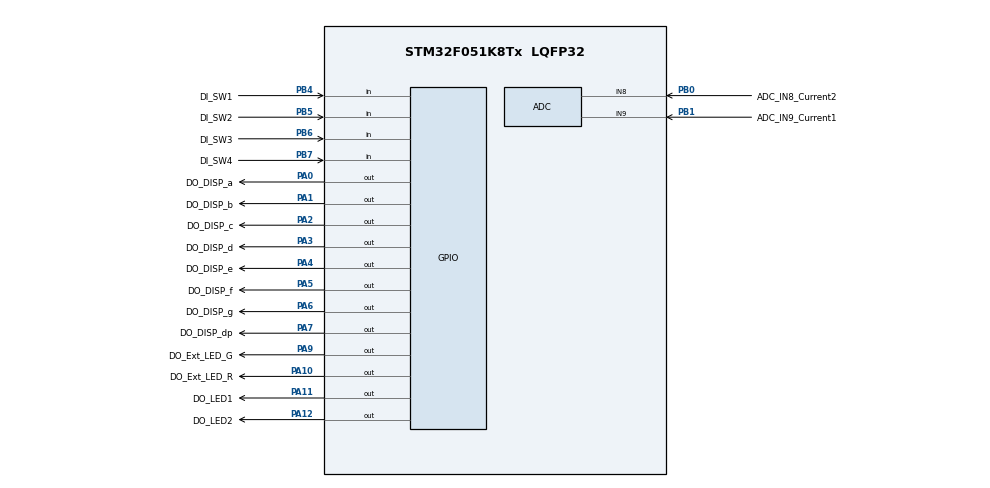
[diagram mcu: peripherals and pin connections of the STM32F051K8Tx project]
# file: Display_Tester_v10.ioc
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ADC.ClockPrescaler=ADC_CLOCK_ASYNC_DIV1
ADC.ContinuousConvMode=ENABLE
ADC.DMAContinuousRequests=ENABLE
ADC.EOCSelection=ADC_EOC_SINGLE_CONV
ADC.SamplingTime=ADC_SAMPLETIME_239CYCLES_5
Dma.ADC.0.Direction=DMA_PERIPH_TO_MEMORY
Dma.ADC.0.Instance=DMA1_Channel1
Dma.ADC.0.MemDataAlignment=DMA_MDATAALIGN_HALFWORD
Dma.ADC.0.MemInc=DMA_MINC_ENABLE
Dma.ADC.0.Mode=DMA_CIRCULAR
Dma.ADC.0.PeriphDataAlignment=DMA_PDATAALIGN_HALFWORD
Dma.ADC.0.PeriphInc=DMA_PINC_DISABLE
Dma.ADC.0.Priority=DMA_PRIORITY_LOW
Dma.Request0=ADC
Mcu.Family=STM32F0
Mcu.Name=STM32F051K8Tx
Mcu.Package=LQFP32
NVIC.DMA1_Channel1_IRQn=true\:0\:0\:false\:false\:true\:false\:true
PA0.GPIO_Label=DO_DISP_a
PA0.Signal=GPIO_Output
PA1.GPIO_Label=DO_DISP_b
PA1.Signal=GPIO_Output
PA10.GPIO_Label=DO_Ext_LED_R
PA10.Signal=GPIO_Output
PA11.GPIO_Label=DO_LED1
PA11.Signal=GPIO_Output
PA12.GPIO_Label=DO_LED2
PA12.Signal=GPIO_Output
PA13.Mode=Serial_Wire
PA13.Signal=SYS_SWDIO
PA14.Mode=Serial_Wire
PA14.Signal=SYS_SWCLK
PA2.GPIO_Label=DO_DISP_c
PA2.Signal=GPIO_Output
PA3.GPIO_Label=DO_DISP_d
PA3.Signal=GPIO_Output
PA4.GPIO_Label=DO_DISP_e
PA4.Signal=GPIO_Output
PA5.GPIO_Label=DO_DISP_f
PA5.Signal=GPIO_Output
PA6.GPIO_Label=DO_DISP_g
PA6.Signal=GPIO_Output
PA7.GPIO_Label=DO_DISP_dp
PA7.Signal=GPIO_Output
PA9.GPIO_Label=DO_Ext_LED_G
PA9.Signal=GPIO_Output
PB0.GPIO_Label=ADC_IN8_Current2
PB0.Mode=IN8
PB0.Signal=ADC_IN8
PB1.GPIO_Label=ADC_IN9_Current1
PB1.Mode=IN9
PB1.Signal=ADC_IN9
PB4.GPIO_Label=DI_SW1
PB4.GPIO_PuPd=GPIO_PULLUP
PB4.Signal=GPIO_Input
PB5.GPIO_Label=DI_SW2
PB5.GPIO_PuPd=GPIO_PULLUP
PB5.Signal=GPIO_Input
PB6.GPIO_Label=DI_SW3
PB6.GPIO_PuPd=GPIO_PULLUP
PB6.Signal=GPIO_Input
PB7.GPIO_Label=DI_SW4
PB7.GPIO_PuPd=GPIO_PULLUP
PB7.Signal=GPIO_Input
PF0-OSC_IN.Mode=HSE-External-Oscillator
PF0-OSC_IN.Signal=RCC_OSC_IN
PF1-OSC_OUT.Mode=HSE-External-Oscillator
PF1-OSC_OUT.Signal=RCC_OSC_OUT
ProjectManager.HeapSize=0x200
ProjectManager.StackSize=0x400
ProjectManager.TargetToolchain=STM32CubeIDE
RCC.AHBFreq_Value=48000000
RCC.APB1Freq_Value=48000000
RCC.APB1TimFreq_Value=48000000
RCC.HCLKFreq_Value=48000000
RCC.PLLMUL=RCC_PLL_MUL6
RCC.PLLSourceVirtual=RCC_PLLSOURCE_HSE
RCC.SYSCLKFreq_VALUE=48000000
RCC.SYSCLKSource=RCC_SYSCLKSOURCE_PLLCLK
board=custom

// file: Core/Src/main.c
/* USER CODE BEGIN Header */
/**
  ******************************************************************************
  * @file           : main.c
  * @brief          : Main program body
  ******************************************************************************
  * @attention
  *
  * <h2><center>&copy; Copyright (c) 2020 STMicroelectronics.
  * All rights reserved.</center></h2>
  *
  * This software component is licensed by ST under BSD 3-Clause license,
  * the "License"; You may not use this file except in compliance with the
  * License. You may obtain a copy of the License at:
  *                        opensource.org/licenses/BSD-3-Clause
  *
  ******************************************************************************
  */
/* USER CODE END Header */
#include "main.h"

ADC_HandleTypeDef hadc;
DMA_HandleTypeDef hdma_adc;

void SystemClock_Config(void);
static void MX_GPIO_Init(void);
static void MX_DMA_Init(void);
static void MX_ADC_Init(void);

int main(void)
{

  /* MCU Configuration--------------------------------------------------------*/

  /* Reset of all peripherals, Initializes the Flash interface and the Systick. */
  HAL_Init();

  /* Configure the system clock */
  SystemClock_Config();

  /* Initialize all configured peripherals */
  MX_GPIO_Init();
  MX_DMA_Init();
  MX_ADC_Init();
  /* USER CODE BEGIN 2 */

  Tester_Init();

  /* USER CODE END 2 */

  /* Infinite loop */
  /* USER CODE BEGIN WHILE */
  while (1)
  {
	  Tester_ProcessingTask();

    /* USER CODE END WHILE */

  }
}

void SystemClock_Config(void)
{
  LL_FLASH_SetLatency(LL_FLASH_LATENCY_1);
  while(LL_FLASH_GetLatency() != LL_FLASH_LATENCY_1)
  {
  }
  LL_RCC_HSE_Enable();

   /* Wait till HSE is ready */
  while(LL_RCC_HSE_IsReady() != 1)
  {

  }
  LL_RCC_HSI14_Enable();

   /* Wait till HSI14 is ready */
  while(LL_RCC_HSI14_IsReady() != 1)
  {

  }
  LL_RCC_HSI14_SetCalibTrimming(16);
  LL_RCC_PLL_ConfigDomain_SYS(LL_RCC_PLLSOURCE_HSE_DIV_1, LL_RCC_PLL_MUL_6);
  LL_RCC_PLL_Enable();

   /* Wait till PLL is ready */
  while(LL_RCC_PLL_IsReady() != 1)
  {

  }
  LL_RCC_SetAHBPrescaler(LL_RCC_SYSCLK_DIV_1);
  LL_RCC_SetAPB1Prescaler(LL_RCC_APB1_DIV_1);
  LL_RCC_SetSysClkSource(LL_RCC_SYS_CLKSOURCE_PLL);

   /* Wait till System clock is ready */
  while(LL_RCC_GetSysClkSource() != LL_RCC_SYS_CLKSOURCE_STATUS_PLL)
  {

  }
  LL_SetSystemCoreClock(48000000);

   /* Update the time base */
  if (HAL_InitTick (TICK_INT_PRIORITY) != HAL_OK)
  {
    Error_Handler();
  }
  LL_RCC_HSI14_EnableADCControl();
}

static void MX_ADC_Init(void)
{

  ADC_ChannelConfTypeDef sConfig = {0};

  /** Configure the global features of the ADC (Clock, Resolution, Data Alignment and number of conversion)
  */
  hadc.Instance = ADC1;
  hadc.Init.ClockPrescaler = ADC_CLOCK_ASYNC_DIV1;
  hadc.Init.Resolution = ADC_RESOLUTION_12B;
  hadc.Init.DataAlign = ADC_DATAALIGN_RIGHT;
  hadc.Init.ScanConvMode = ADC_SCAN_DIRECTION_FORWARD;
  hadc.Init.EOCSelection = ADC_EOC_SINGLE_CONV;
  hadc.Init.LowPowerAutoWait = DISABLE;
  hadc.Init.LowPowerAutoPowerOff = DISABLE;
  hadc.Init.ContinuousConvMode = ENABLE;
  hadc.Init.DiscontinuousConvMode = DISABLE;
  hadc.Init.ExternalTrigConv = ADC_SOFTWARE_START;
  hadc.Init.ExternalTrigConvEdge = ADC_EXTERNALTRIGCONVEDGE_NONE;
  hadc.Init.DMAContinuousRequests = ENABLE;
  hadc.Init.Overrun = ADC_OVR_DATA_PRESERVED;
  if (HAL_ADC_Init(&hadc) != HAL_OK)
  {
    Error_Handler();
  }
  /** Configure for the selected ADC regular channel to be converted.
  */
  sConfig.Channel = ADC_CHANNEL_8;
  sConfig.Rank = ADC_RANK_CHANNEL_NUMBER;
  sConfig.SamplingTime = ADC_SAMPLETIME_239CYCLES_5;
  if (HAL_ADC_ConfigChannel(&hadc, &sConfig) != HAL_OK)
  {
    Error_Handler();
  }
  /** Configure for the selected ADC regular channel to be converted.
  */
  sConfig.Channel = ADC_CHANNEL_9;
  if (HAL_ADC_ConfigChannel(&hadc, &sConfig) != HAL_OK)
  {
    Error_Handler();
  }

}

static void MX_DMA_Init(void)
{

  /* DMA controller clock enable */
  __HAL_RCC_DMA1_CLK_ENABLE();

  /* DMA interrupt init */
  /* DMA1_Channel1_IRQn interrupt configuration */
  HAL_NVIC_SetPriority(DMA1_Channel1_IRQn, 0, 0);
  HAL_NVIC_EnableIRQ(DMA1_Channel1_IRQn);

}

static void MX_GPIO_Init(void)
{
  LL_GPIO_InitTypeDef GPIO_InitStruct = {0};

  /* GPIO Ports Clock Enable */
  LL_AHB1_GRP1_EnableClock(LL_AHB1_GRP1_PERIPH_GPIOF);
  LL_AHB1_GRP1_EnableClock(LL_AHB1_GRP1_PERIPH_GPIOA);
  LL_AHB1_GRP1_EnableClock(LL_AHB1_GRP1_PERIPH_GPIOB);

  /**/
  LL_GPIO_ResetOutputPin(DO_DISP_a_GPIO_Port, DO_DISP_a_Pin);

  /**/
  LL_GPIO_ResetOutputPin(DO_DISP_b_GPIO_Port, DO_DISP_b_Pin);

  /**/
  LL_GPIO_ResetOutputPin(DO_DISP_c_GPIO_Port, DO_DISP_c_Pin);

  /**/
  LL_GPIO_ResetOutputPin(DO_DISP_d_GPIO_Port, DO_DISP_d_Pin);

  /**/
  LL_GPIO_ResetOutputPin(DO_DISP_e_GPIO_Port, DO_DISP_e_Pin);

  /**/
  LL_GPIO_ResetOutputPin(DO_DISP_f_GPIO_Port, DO_DISP_f_Pin);

  /**/
  LL_GPIO_ResetOutputPin(DO_DISP_g_GPIO_Port, DO_DISP_g_Pin);

  /**/
  LL_GPIO_ResetOutputPin(DO_DISP_dp_GPIO_Port, DO_DISP_dp_Pin);

  /**/
  LL_GPIO_ResetOutputPin(DO_Ext_LED_G_GPIO_Port, DO_Ext_LED_G_Pin);

  /**/
  LL_GPIO_ResetOutputPin(DO_Ext_LED_R_GPIO_Port, DO_Ext_LED_R_Pin);

  /**/
  LL_GPIO_ResetOutputPin(DO_LED1_GPIO_Port, DO_LED1_Pin);

  /**/
  LL_GPIO_ResetOutputPin(DO_LED2_GPIO_Port, DO_LED2_Pin);

  /**/
  GPIO_InitStruct.Pin = DO_DISP_a_Pin;
  GPIO_InitStruct.Mode = LL_GPIO_MODE_OUTPUT;
  GPIO_InitStruct.Speed = LL_GPIO_SPEED_FREQ_LOW;
  GPIO_InitStruct.OutputType = LL_GPIO_OUTPUT_PUSHPULL;
  GPIO_InitStruct.Pull = LL_GPIO_PULL_NO;
  LL_GPIO_Init(DO_DISP_a_GPIO_Port, &GPIO_InitStruct);

  /**/
  GPIO_InitStruct.Pin = DO_DISP_b_Pin;
  GPIO_InitStruct.Mode = LL_GPIO_MODE_OUTPUT;
  GPIO_InitStruct.Speed = LL_GPIO_SPEED_FREQ_LOW;
  GPIO_InitStruct.OutputType = LL_GPIO_OUTPUT_PUSHPULL;
  GPIO_InitStruct.Pull = LL_GPIO_PULL_NO;
  LL_GPIO_Init(DO_DISP_b_GPIO_Port, &GPIO_InitStruct);

  /**/
  GPIO_InitStruct.Pin = DO_DISP_c_Pin;
  GPIO_InitStruct.Mode = LL_GPIO_MODE_OUTPUT;
  GPIO_InitStruct.Speed = LL_GPIO_SPEED_FREQ_LOW;
  GPIO_InitStruct.OutputType = LL_GPIO_OUTPUT_PUSHPULL;
  GPIO_InitStruct.Pull = LL_GPIO_PULL_NO;
  LL_GPIO_Init(DO_DISP_c_GPIO_Port, &GPIO_InitStruct);

  /**/
  GPIO_InitStruct.Pin = DO_DISP_d_Pin;
  GPIO_InitStruct.Mode = LL_GPIO_MODE_OUTPUT;
  GPIO_InitStruct.Speed = LL_GPIO_SPEED_FREQ_LOW;
  GPIO_InitStruct.OutputType = LL_GPIO_OUTPUT_PUSHPULL;
  GPIO_InitStruct.Pull = LL_GPIO_PULL_NO;
  LL_GPIO_Init(DO_DISP_d_GPIO_Port, &GPIO_InitStruct);

  /**/
  GPIO_InitStruct.Pin = DO_DISP_e_Pin;
  GPIO_InitStruct.Mode = LL_GPIO_MODE_OUTPUT;
  GPIO_InitStruct.Speed = LL_GPIO_SPEED_FREQ_LOW;
  GPIO_InitStruct.OutputType = LL_GPIO_OUTPUT_PUSHPULL;
  GPIO_InitStruct.Pull = LL_GPIO_PULL_NO;
  LL_GPIO_Init(DO_DISP_e_GPIO_Port, &GPIO_InitStruct);

  /**/
  GPIO_InitStruct.Pin = DO_DISP_f_Pin;
  GPIO_InitStruct.Mode = LL_GPIO_MODE_OUTPUT;
  GPIO_InitStruct.Speed = LL_GPIO_SPEED_FREQ_LOW;
  GPIO_InitStruct.OutputType = LL_GPIO_OUTPUT_PUSHPULL;
  GPIO_InitStruct.Pull = LL_GPIO_PULL_NO;
  LL_GPIO_Init(DO_DISP_f_GPIO_Port, &GPIO_InitStruct);

  /**/
  GPIO_InitStruct.Pin = DO_DISP_g_Pin;
  GPIO_InitStruct.Mode = LL_GPIO_MODE_OUTPUT;
  GPIO_InitStruct.Speed = LL_GPIO_SPEED_FREQ_LOW;
  GPIO_InitStruct.OutputType = LL_GPIO_OUTPUT_PUSHPULL;
  GPIO_InitStruct.Pull = LL_GPIO_PULL_NO;
  LL_GPIO_Init(DO_DISP_g_GPIO_Port, &GPIO_InitStruct);

  /**/
  GPIO_InitStruct.Pin = DO_DISP_dp_Pin;
  GPIO_InitStruct.Mode = LL_GPIO_MODE_OUTPUT;
  GPIO_InitStruct.Speed = LL_GPIO_SPEED_FREQ_LOW;
  GPIO_InitStruct.OutputType = LL_GPIO_OUTPUT_PUSHPULL;
  GPIO_InitStruct.Pull = LL_GPIO_PULL_NO;
  LL_GPIO_Init(DO_DISP_dp_GPIO_Port, &GPIO_InitStruct);

  /**/
  GPIO_InitStruct.Pin = LL_GPIO_PIN_8;
  GPIO_InitStruct.Mode = LL_GPIO_MODE_ANALOG;
  GPIO_InitStruct.Pull = LL_GPIO_PULL_NO;
  LL_GPIO_Init(GPIOA, &GPIO_InitStruct);

  /**/
  GPIO_InitStruct.Pin = DO_Ext_LED_G_Pin;
  GPIO_InitStruct.Mode = LL_GPIO_MODE_OUTPUT;
  GPIO_InitStruct.Speed = LL_GPIO_SPEED_FREQ_LOW;
  GPIO_InitStruct.OutputType = LL_GPIO_OUTPUT_PUSHPULL;
  GPIO_InitStruct.Pull = LL_GPIO_PULL_NO;
  LL_GPIO_Init(DO_Ext_LED_G_GPIO_Port, &GPIO_InitStruct);

  /**/
  GPIO_InitStruct.Pin = DO_Ext_LED_R_Pin;
  GPIO_InitStruct.Mode = LL_GPIO_MODE_OUTPUT;
  GPIO_InitStruct.Speed = LL_GPIO_SPEED_FREQ_LOW;
  GPIO_InitStruct.OutputType = LL_GPIO_OUTPUT_PUSHPULL;
  GPIO_InitStruct.Pull = LL_GPIO_PULL_NO;
  LL_GPIO_Init(DO_Ext_LED_R_GPIO_Port, &GPIO_InitStruct);

  /**/
  GPIO_InitStruct.Pin = DO_LED1_Pin;
  GPIO_InitStruct.Mode = LL_GPIO_MODE_OUTPUT;
  GPIO_InitStruct.Speed = LL_GPIO_SPEED_FREQ_LOW;
  GPIO_InitStruct.OutputType = LL_GPIO_OUTPUT_PUSHPULL;
  GPIO_InitStruct.Pull = LL_GPIO_PULL_NO;
  LL_GPIO_Init(DO_LED1_GPIO_Port, &GPIO_InitStruct);

  /**/
  GPIO_InitStruct.Pin = DO_LED2_Pin;
  GPIO_InitStruct.Mode = LL_GPIO_MODE_OUTPUT;
  GPIO_InitStruct.Speed = LL_GPIO_SPEED_FREQ_LOW;
  GPIO_InitStruct.OutputType = LL_GPIO_OUTPUT_PUSHPULL;
  GPIO_InitStruct.Pull = LL_GPIO_PULL_NO;
  LL_GPIO_Init(DO_LED2_GPIO_Port, &GPIO_InitStruct);

  /**/
  GPIO_InitStruct.Pin = LL_GPIO_PIN_15;
  GPIO_InitStruct.Mode = LL_GPIO_MODE_ANALOG;
  GPIO_InitStruct.Pull = LL_GPIO_PULL_NO;
  LL_GPIO_Init(GPIOA, &GPIO_InitStruct);

  /**/
  GPIO_InitStruct.Pin = LL_GPIO_PIN_3;
  GPIO_InitStruct.Mode = LL_GPIO_MODE_ANALOG;
  GPIO_InitStruct.Pull = LL_GPIO_PULL_NO;
  LL_GPIO_Init(GPIOB, &GPIO_InitStruct);

  /**/
  GPIO_InitStruct.Pin = DI_SW1_Pin;
  GPIO_InitStruct.Mode = LL_GPIO_MODE_INPUT;
  GPIO_InitStruct.Pull = LL_GPIO_PULL_UP;
  LL_GPIO_Init(DI_SW1_GPIO_Port, &GPIO_InitStruct);

  /**/
  GPIO_InitStruct.Pin = DI_SW2_Pin;
  GPIO_InitStruct.Mode = LL_GPIO_MODE_INPUT;
  GPIO_InitStruct.Pull = LL_GPIO_PULL_UP;
  LL_GPIO_Init(DI_SW2_GPIO_Port, &GPIO_InitStruct);

  /**/
  GPIO_InitStruct.Pin = DI_SW3_Pin;
  GPIO_InitStruct.Mode = LL_GPIO_MODE_INPUT;
  GPIO_InitStruct.Pull = LL_GPIO_PULL_UP;
  LL_GPIO_Init(DI_SW3_GPIO_Port, &GPIO_InitStruct);

  /**/
  GPIO_InitStruct.Pin = DI_SW4_Pin;
  GPIO_InitStruct.Mode = LL_GPIO_MODE_INPUT;
  GPIO_InitStruct.Pull = LL_GPIO_PULL_UP;
  LL_GPIO_Init(DI_SW4_GPIO_Port, &GPIO_InitStruct);

}

void Error_Handler(void)
{
}

/************************ (C) COPYRIGHT STMicroelectronics *****END OF FILE****/
